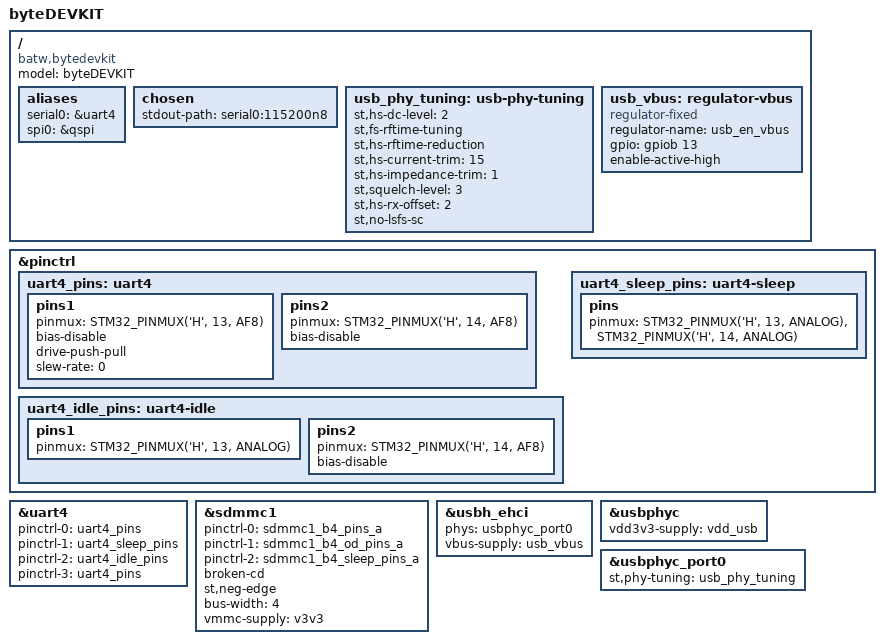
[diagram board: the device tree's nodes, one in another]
// SPDX-License-Identifier: GPL-2.0
/*
 *  Copyright (C) 2019 bytes at work AG - http://www.bytesatwork.ch
 */

/dts-v1/;

#include "stm32mp157c-byteengine-m5.dtsi"

/ {
	model = "byteDEVKIT";
	compatible = "batw,bytedevkit", "batw,m5", "st,stm32mp157";

	aliases {
		serial0 = &uart4;
		spi0 = &qspi;
	};

	chosen {
		stdout-path = "serial0:115200n8";
	};

	usb_phy_tuning: usb-phy-tuning {
		st,hs-dc-level = <2>;
		st,fs-rftime-tuning;
		st,hs-rftime-reduction;
		st,hs-current-trim = <15>;
		st,hs-impedance-trim = <1>;
		st,squelch-level = <3>;
		st,hs-rx-offset = <2>;
		st,no-lsfs-sc;
	};

	usb_vbus: regulator-vbus {
		compatible = "regulator-fixed";
		regulator-name = "usb_en_vbus";
		gpio = <&gpiob 13 GPIO_ACTIVE_HIGH>;
		enable-active-high;
	};
};

&pinctrl {
	uart4_pins: uart4 {
		pins1 {
			pinmux = <STM32_PINMUX('H', 13, AF8)>; /* UART4_TX */
			bias-disable;
			drive-push-pull;
			slew-rate = <0>;
		};

		pins2 {
			pinmux = <STM32_PINMUX('H', 14, AF8)>; /* UART4_RX */
			bias-disable;
		};
	};

	uart4_idle_pins: uart4-idle {
		pins1 {
			pinmux = <STM32_PINMUX('H', 13, ANALOG)>; /* UART4_TX */
		};

		pins2 {
			pinmux = <STM32_PINMUX('H', 14, AF8)>; /* UART4_RX */
			bias-disable;
		};
	};

	uart4_sleep_pins: uart4-sleep {
		pins {
			pinmux = <STM32_PINMUX('H', 13, ANALOG)>, /* UART4_TX */
				 <STM32_PINMUX('H', 14, ANALOG)>; /* UART4_RX */
		};
	};
};

&uart4 {
	pinctrl-names = "default", "sleep", "idle", "no_console_suspend";
	pinctrl-0 = <&uart4_pins>;
	pinctrl-1 = <&uart4_sleep_pins>;
	pinctrl-2 = <&uart4_idle_pins>;
	pinctrl-3 = <&uart4_pins>;
	status = "okay";
};

&sdmmc1 {
	pinctrl-names = "default", "opendrain", "sleep";
	pinctrl-0 = <&sdmmc1_b4_pins_a>;
	pinctrl-1 = <&sdmmc1_b4_od_pins_a>;
	pinctrl-2 = <&sdmmc1_b4_sleep_pins_a>;
	broken-cd;
	st,neg-edge;
	bus-width = <4>;
	vmmc-supply = <&v3v3>;
	status = "okay";
};

&usbh_ehci {
	phys = <&usbphyc_port0>;
	phy-names = "usb";
	vbus-supply = <&usb_vbus>;
	status = "okay";
};

&usbphyc {
	vdd3v3-supply = <&vdd_usb>;
	status = "okay";
};

&usbphyc_port0 {
	st,phy-tuning = <&usb_phy_tuning>;
};
